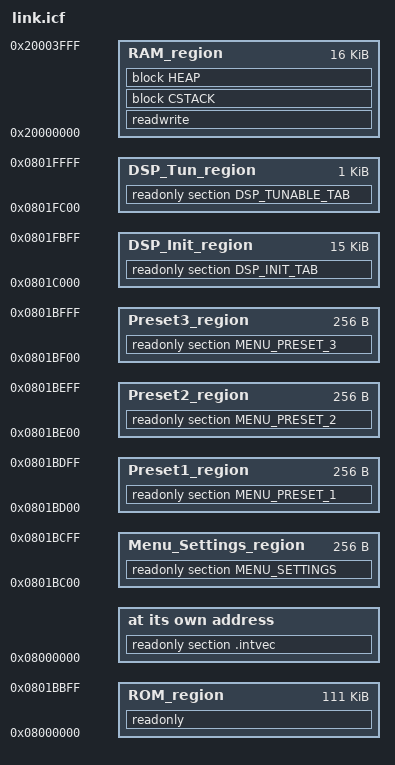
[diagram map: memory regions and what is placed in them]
/*###ICF### Section handled by ICF editor, don't touch! ****/
/*-Editor annotation file-*/
/* IcfEditorFile="$TOOLKIT_DIR$\config\ide\IcfEditor\cortex_v1_0.xml" */
/*-Specials-*/
define symbol __ICFEDIT_intvec_start__ = 0x08000000;
/*-Memory Regions-*/
define symbol __ICFEDIT_region_ROM_start__ = 0x08000000;
define symbol __ICFEDIT_region_ROM_end__   = 0x0801BBFF;
define symbol __ICFEDIT_region_RAM_start__ = 0x20000000;
define symbol __ICFEDIT_region_RAM_end__   = 0x20003FFF;

/*-ROM region to store settings-*/
define symbol __USEREDIT_region_MenuSettings_start__ = 0x0801BC00;
define symbol __USEREDIT_region_MenuSettings_end__   = 0x0801BCFF;
define symbol __USEREDIT_region_Preset1_start__ = 0x0801BD00;
define symbol __USEREDIT_region_Preset1_end__   = 0x0801BDFF;
define symbol __USEREDIT_region_Preset2_start__ = 0x0801BE00;
define symbol __USEREDIT_region_Preset2_end__   = 0x0801BEFF;
define symbol __USEREDIT_region_Preset3_start__ = 0x0801BF00;
define symbol __USEREDIT_region_Preset3_end__   = 0x0801BFFF;
/*-ROM region to store DSP Init Table, 15k Bytes-*/
define symbol __USEREDIT_region_DSP_Init_start__ = 0x0801C000;
define symbol __USEREDIT_region_DSP_Init_end__   = 0x0801FBFF;
/*-ROM region to store DSP Tunable Table, 1k Bytes-*/
define symbol __USEREDIT_region_DSP_Tun_start__ = 0x0801FC00;
define symbol __USEREDIT_region_DSP_Tun_end__   = 0x0801FFFF;


/*-Sizes-*/
define symbol __ICFEDIT_size_cstack__ = 0x400;
define symbol __ICFEDIT_size_heap__   = 0x200;
/**** End of ICF editor section. ###ICF###*/


define memory mem with size = 4G;
define region ROM_region   = mem:[from __ICFEDIT_region_ROM_start__   to __ICFEDIT_region_ROM_end__];
define region RAM_region   = mem:[from __ICFEDIT_region_RAM_start__   to __ICFEDIT_region_RAM_end__];

/*-ROM region to store Settings-*/
define region Menu_Settings_region  = mem:[from __USEREDIT_region_MenuSettings_start__ to __USEREDIT_region_MenuSettings_end__];
define region Preset1_region  = mem:[from __USEREDIT_region_Preset1_start__ to __USEREDIT_region_Preset1_end__];
define region Preset2_region  = mem:[from __USEREDIT_region_Preset2_start__ to __USEREDIT_region_Preset2_end__];
define region Preset3_region  = mem:[from __USEREDIT_region_Preset3_start__ to __USEREDIT_region_Preset3_end__];
/*-ROM region to store DSP Init Table-*/
define region DSP_Init_region  = mem:[from __USEREDIT_region_DSP_Init_start__ to __USEREDIT_region_DSP_Init_end__];
/*-ROM region to store DSP Tunable Table-*/
define region DSP_Tun_region  = mem:[from __USEREDIT_region_DSP_Tun_start__ to __USEREDIT_region_DSP_Tun_end__];



export symbol __ICFEDIT_region_RAM_start__;
export symbol __ICFEDIT_region_RAM_end__;
define block CSTACK    with alignment = 8, size = __ICFEDIT_size_cstack__   { };
define block HEAP      with alignment = 8, size = __ICFEDIT_size_heap__     { };

initialize by copy { readwrite };
do not initialize  { section .noinit };

place at address mem:__ICFEDIT_intvec_start__ { readonly section .intvec };

place in ROM_region   { readonly };
place in RAM_region   { readwrite,
                        block CSTACK, block HEAP };

/*-place Settings in ROM-*/
place in Menu_Settings_region  { readonly section MENU_SETTINGS };
place in Preset1_region  { readonly section MENU_PRESET_1 };
place in Preset2_region  { readonly section MENU_PRESET_2 };
place in Preset3_region  { readonly section MENU_PRESET_3 };
/*-place DSP Table in DSP_Init-*/
place in DSP_Init_region  { readonly section DSP_INIT_TAB};
/*-place DSP Table in DSP_Tun-*/
place in DSP_Tun_region  { readonly section DSP_TUNABLE_TAB};

